# XMC4100 register map
Vendor: Infineon; File version: 1.5.2 (Reference Manual v1.5)
CPU: CM4 r2p0, little endian, MPU, FPU, 6 interrupt priority bits
Registers are 32-bit, read-write, reset 0x0 unless marked. A register's access mark holds for its fields unless they carry their own. Offsets are from the block's base; [hi:lo] are bit positions; {n}, {i} and the like mark numbered series; 'fields as' and 'values as' point back to an identical list.

## HRPWM0_HRC0 — High Resolution PWM Unit
Base 0x40021300
Same registers: HRPWM0_HRC1 0x40021400, HRPWM0_HRC2 0x40021500, HRPWM0_HRC3 0x40021600
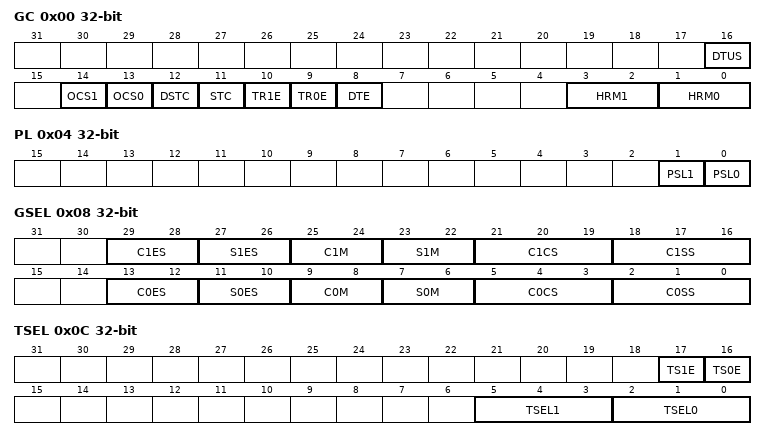
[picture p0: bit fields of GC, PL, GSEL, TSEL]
0x00 GC — HRC mode configuration
  [16] DTUS — Dead Time update trigger selector
    0=The update of the values is done with the trigger generated by the timers. This is the same trigger that is used to update the HRCyCR1This register holds the value for the rising edge high resolution signal placement. the update of this value should be done via the associated shadow register, . and HRCyCR2This register holds the value for the falling edge high resolution signal placement. the update of this value should be done via the associated shadow register, ..; 1=The update of the dead time values is done when the dead time counter is not running, independently of the HRCyCR1This register holds the value for the rising edge high resolution signal placement. the update of this value should be done via the associated shadow register, . and HRCyCR2This register holds the value for the falling edge high resolution signal placement. the update of this value should be done via the associated shadow register, . registers.
  [14] OCS1 — HRPWMx.OUTy1 channel selector
    0=HRPWMx.OUTy1 is connected to the latch Qn channel; 1=HRPWMx.OUTy1 is connected to the latch Q channel
  [13] OCS0 — HRPWMx.OUTy0 channel selector
    0=HRPWMx.OUTy0 is connected to the latch Q channel; 1=HRPWMx.OUTy0 is connected to the latch Qn channel
  [12] DSTC — HRCy dead time shadow transfer configuration
    0=HRCy shadow transfer enable for HRCyDCRThis register holds the dead time value that is going to be inserted whenever a rising transition on the output latch is sensed. and HRCyDCFThis register holds the dead time value that is going to be inserted whenever a falling transition on the output latch is sensed. values is not linked with the specific Capture/Compare Unit timer.; 1=HRCy shadow transfer enable for HRCyDCRThis register holds the dead time value that is going to be inserted whenever a rising transition on the output latch is sensed. and HRCyDCFThis register holds the dead time value that is going to be inserted whenever a falling transition on the output latch is sensed. values is linked with the specific Capture/Compare Unit timer.
  [11] STC — HRCy shadow transfer configuration
    0=HRCy shadow transfer enable for HRCyCR1This register holds the value for the rising edge high resolution signal placement. the update of this value should be done via the associated shadow register, . and HRCyCR2This register holds the value for the falling edge high resolution signal placement. the update of this value should be done via the associated shadow register, . values is not linked with the specific Capture/Compare Unit timer.; 1=HRCy shadow transfer enable for HRCyCR1This register holds the value for the rising edge high resolution signal placement. the update of this value should be done via the associated shadow register, . and HRCyCR2This register holds the value for the falling edge high resolution signal placement. the update of this value should be done via the associated shadow register, . values is linked with the specific Capture/Compare Unit timer.
  [10] TR1E — HRCy complementary trap enable
    0=Trap function for HRPWMx.HROUTy1 is disabled; 1=Trap function for HRPWMx.HROUTy1 is enabled
  [9] TR0E — HRCy trap enable
    0=Trap function for HRPWMx.HROUTy0 is disabled; 1=Trap function for HRPWMx.HROUTy0 is enabled
  [8] DTE — HRCy dead time enable
    0=Dead time insertion is disabled; 1=Dead time insertion is enabled
  [3:2] HRM1 — HRCy high resolution mode configuration for source selector 1
    0=Rising edge high resolution signal positioning enabled; 1=Falling edge high resolution signal positioning enabled; 2=Both edges high resolution signal positioning is enabled; 3=No high resolution positioning
  [1:0] HRM0 — HRCy high resolution mode configuration for source selector 0
    values as HRM1
0x04 PL — HRC output passive level
  [1] PSL1 — HRPWMx.OUTy1 passive level
    0=HRPWMx.OUTy1 output passive level is set to LOW; 1=HRPWMx.OUTy1 output passive level is set to HIGH
  [0] PSL0 — HRPWMx.OUTy0 passive level
    0=HRPWMx.OUTy0 output passive level is set to LOW; 1=HRPWMx.OUTy0 output passive level is set to HIGH
0x08 GSEL — HRC global control selection
  [29:28] C1ES — Source selector 1 clear edge configuration
    0=Generation of the clear signal is disabled; 1=Clear signal is generated on a LOW to HIGH transition of the selected input; 2=Clear signal is generated on a HIGH to LOW transition of the selected input; 3=Clear signal is generated on both transitions of the selected input
  [27:26] S1ES — Source selector 1 set edge configuration
    0=Generation of the set signal is disabled; 1=Set signal is generated on a LOW to HIGH transition of the selected input; 2=Set signal is generated on a HIGH to LOW transition of the selected input; 3=Set signal is generated on both transitions of the selected input
  [25:24] C1M — Source selector 1 clear configuration
    0=Clear from source selector 1 is controlled via the Capture/Compare Unit timer, CCSTy signal; 1=Clear from source selector 1 is controlled via the CMP output from the CSGy unit. Which unit is being used is configured via the C1CS field.
  [23:22] S1M — Source selector 1 set configuration
    0=Set from source selector 1 is controlled via the Capture/Compare Unit timer, CCSTy signal; 1=Set from source selector 1 is controlled via the CMP output from the CSGy unit. Which unit is being used is configured via the C1SS field.
  [21:19] C1CS — Source selector 1 comparator clear configuration
    0=CMP output of CSG0 unit can be used as clear source for the output latch; 1=CMP output of CSG2 unit can be used as clear source for the output latch; 2=CMP output of CSG2 unit can be used as clear source for the output latch
  [18:16] C1SS — Source selector 1 comparator set configuration
    0=CMP output of CSG0 unit can be used as set source for the output latch; 1=CMP output of CSG2 unit can be used as set source for the output latch; 2=CMP output of CSG2 unit can be used as set source for the output latch
  [13:12] C0ES — Source selector 0 clear edge configuration
    values as C1ES
  [11:10] S0ES — Source selector 0 set edge configuration
    values as S1ES
  [9:8] C0M — Source selector 0 clear configuration
    0=Clear from source selector 0 is controlled via the Capture/Compare Unit timer, CCSTy signal; 1=Clear from source selector 0 is controlled via the CMP output from the CSGy unit. Which unit is being used is configured via the C0CS field.
  [7:6] S0M — Source selector 0 set configuration
    0=Set from source selector 0 is controlled via the Capture/Compare Unit timer, CCSTy signal; 1=Set from source selector 0 is controlled via the CMP output from the CSGy unit. Which unit is being used is configured via the C0SS field.
  [5:3] C0CS — Source selector 0 comparator clear configuration
    0=CMP output of CSG0 unit can be used as clear source for the output latch; 1=CMP output of CSG1 unit can be used as clear source for the output latch; 2=CMP output of CSG2 unit can be used as clear source for the output latch
  [2:0] C0SS — Source selector 0 comparator set configuration
    0=CMP output of CSG0 unit can be used as set source for the output latch; 1=CMP output of CSG1 unit can be used as set source for the output latch; 2=CMP output of CSG2 unit can be used as set source for the output latch
0x0C TSEL — HRC timer selection
  [17] TS1E — Source selector 1 TRAP enable
    0=TRAP signal generated from the Timer connected to Source Selector 1 is disabled; 1=TRAP signal generated from the Timer connected to Source Selector 1 is enabled
  [16] TS0E — Source selector 0 TRAP enable
    0=TRAP signal generated from the Timer connected to Source Selector 0 is disabled; 1=TRAP signal generated from the Timer connected to Source Selector 0 is enabled
  [5:3] TSEL1 — Source Selector 1 Timer connection
    {v}=Source Selector 1 is connected to Capture/Compare Unit Timer {v} (CCST{v} can be used) (v=0..3)
  [2:0] TSEL0 — Source Selector 0 Timer connection
    {v}=Source Selector 0 is connected to Capture/Compare Unit Timer {v} (CCST{v} can be used) (v=0..3)
0x10 SC ro — HRC current source for shadow
  [0] ST — Source selector for the shadow transfer
    0=Shadow transfer signals (shadow transfer trigger and shadow transfer enable) are linked with the timer CC8y connected to the Source Selector 0; 1=Shadow transfer signals (shadow transfer trigger and shadow transfer enable) are linked with the timer CC8y connected to the Source Selector 1
0x14 DCR ro reset 0x1 — HRC dead time rising value
  [15:0] DTRV — Dead time rising value
0x18 DCF ro reset 0x1 — HRC dead time falling value
  [15:0] DTFV — Dead time falling value
0x1C CR1 ro — HRC rising edge value
  [7:0] CR1 — High resolution rising edge value
0x20 CR2 ro — HRC falling edge value
  [7:0] CR2 — High resolution falling edge value
0x24 SSC — HRC next source for shadow
  [0] SST — Source selector for the shadow transfer
    0=Next shadow transfer signals (shadow transfer trigger and shadow transfer enable) are linked with the timer CC8y connected to the Source Selector 0; 1=Next shadow transfer signals (shadow transfer trigger and shadow transfer enable) are linked with the timer CC8y connected to the Source Selector 1
0x28 SDCR reset 0x1 — HRC shadow dead time rising
  [15:0] SDTRV — Shadow dead time rising value
0x2C SDCF reset 0x1 — HRC shadow dead time falling
  [15:0] SDTFV — Shadow dead time falling value
0x30 SCR1 — HRC shadow rising edge value
  [7:0] SCR1 — High resolution falling edge value
0x34 SCR2 — HRC shadow falling edge value
  [7:0] SCR2 — High resolution rising edge value

## Notices in the file
Copyright (C) 2016 Infineon Technologies AG. All rights reserved.
Infineon Technologies AG (Infineon) is supplying this software for use with
Infineon's microcontrollers.  This file can be freely distributed within
development tools that are supporting such microcontrollers.
THIS SOFTWARE IS PROVIDED "AS IS".  NO WARRANTIES, WHETHER EXPRESS, IMPLIED
OR STATUTORY, INCLUDING, BUT NOT LIMITED TO, IMPLIED WARRANTIES OF
MERCHANTABILITY AND FITNESS FOR A PARTICULAR PURPOSE APPLY TO THIS SOFTWARE.
INFINEON SHALL NOT, IN ANY CIRCUMSTANCES, BE LIABLE FOR SPECIAL, INCIDENTAL,
OR CONSEQUENTIAL DAMAGES, FOR ANY REASON WHATSOEVER.
